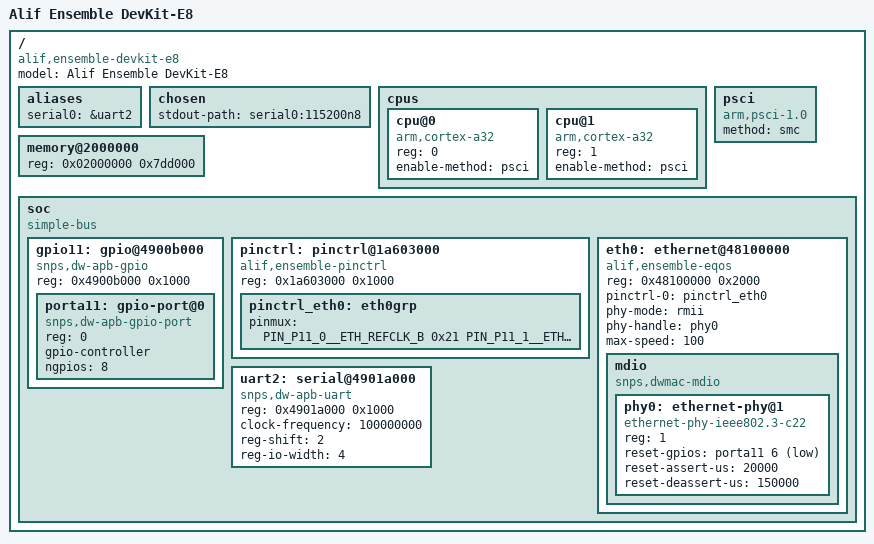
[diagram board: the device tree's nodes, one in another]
// SPDX-License-Identifier: GPL-2.0+
/*
 * Copyright (C) 2026 Analog Devices, Inc.
 */
/dts-v1/;

#include <dt-bindings/gpio/gpio.h>
#include <dt-bindings/pinctrl/alif,ensemble-pinfunc.h>

/ {
	model = "Alif Ensemble DevKit-E8";
	compatible = "alif,ensemble-devkit-e8", "alif,ensemble";
	#address-cells = <1>;
	#size-cells = <1>;

	aliases {
		serial0 = &uart2;
	};

	chosen {
		stdout-path = "serial0:115200n8";
		bootph-all;
	};

	cpus {
		#address-cells = <1>;
		#size-cells = <0>;

		cpu@0 {
			compatible = "arm,cortex-a32";
			device_type = "cpu";
			reg = <0>;
			enable-method = "psci";
		};

		cpu@1 {
			compatible = "arm,cortex-a32";
			device_type = "cpu";
			reg = <1>;
			enable-method = "psci";
		};
	};

	psci {
		compatible = "arm,psci-1.0";
		method = "smc";
		bootph-all;
	};

	/*
	 * SRAM0 and SRAM1 are stitched. The top 0x23000 bytes are used by IPC
	 * shared memory, TF-A and the MHU services.
	 */
	memory@2000000 {
		device_type = "memory";
		reg = <0x02000000 0x7dd000>;
	};

	soc {
		compatible = "simple-bus";
		#address-cells = <1>;
		#size-cells = <1>;
		ranges;
		bootph-all;

		gpio11: gpio@4900b000 {
			compatible = "snps,dw-apb-gpio";
			reg = <0x4900b000 0x1000>;
			#address-cells = <1>;
			#size-cells = <0>;

			porta11: gpio-port@0 {
				compatible = "snps,dw-apb-gpio-port";
				reg = <0>;
				gpio-controller;
				#gpio-cells = <2>;
				ngpios = <8>;
			};
		};

		pinctrl: pinctrl@1a603000 {
			compatible = "alif,ensemble-pinctrl";
			reg = <0x1a603000 0x1000>;

			/*
			 * The pad settings are those of the Alif reference BSP.
			 * The reset of the PHY is a GPIO here, because the
			 * ETH_RST function does not reset the PHY at power on.
			 */
			pinctrl_eth0: eth0grp {
				pinmux = <
					PIN_P11_0__ETH_REFCLK_B		0x21
					PIN_P11_1__ETH_MDIO_B		0x29
					PIN_P11_2__ETH_MDC_B		0x28
					PIN_P11_3__ETH_RXD0_B		0x21
					PIN_P11_4__ETH_RXD1_B		0x21
					PIN_P11_5__ETH_CRS_DV_B		0x21
					PIN_P11_6__GPIO		0x20
					PIN_P11_7__ETH_IRQ_B		0x21
					PIN_P6_0__ETH_TXD0_A		0x20
					PIN_P10_5__ETH_TXD1_B		0x20
					PIN_P10_6__ETH_TXEN_B		0x20
				>;
			};
		};

		eth0: ethernet@48100000 {
			compatible = "alif,ensemble-eqos";
			reg = <0x48100000 0x2000>;
			pinctrl-names = "default";
			pinctrl-0 = <&pinctrl_eth0>;
			phy-mode = "rmii";
			phy-handle = <&phy0>;
			max-speed = <100>;

			mdio {
				compatible = "snps,dwmac-mdio";
				#address-cells = <1>;
				#size-cells = <0>;

				phy0: ethernet-phy@1 {
					compatible = "ethernet-phy-ieee802.3-c22";
					reg = <1>;
					reset-gpios = <&porta11 6 GPIO_ACTIVE_LOW>;
					reset-assert-us = <20000>;
					reset-deassert-us = <150000>;
				};
			};
		};

		uart2: serial@4901a000 {
			compatible = "snps,dw-apb-uart";
			reg = <0x4901a000 0x1000>;
			clock-frequency = <100000000>;
			reg-shift = <2>;
			reg-io-width = <4>;
			bootph-all;
		};
	};
};
